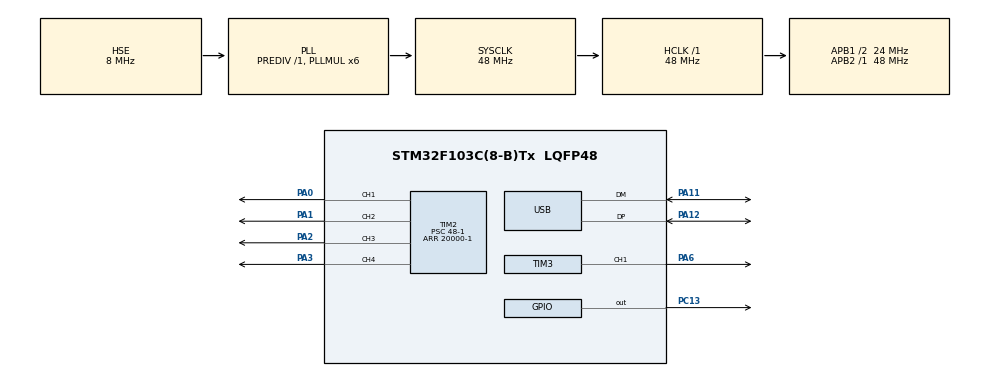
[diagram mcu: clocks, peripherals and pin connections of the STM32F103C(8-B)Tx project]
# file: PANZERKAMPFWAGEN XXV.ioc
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Mcu.Family=STM32F1
Mcu.Name=STM32F103C(8-B)Tx
Mcu.Package=LQFP48
NVIC.PriorityGroup=NVIC_PRIORITYGROUP_4
NVIC.USB_LP_CAN1_RX0_IRQn=true\:0\:0\:false\:false\:true\:false\:true
PA0-WKUP.Signal=S_TIM2_CH1_ETR
PA1.Signal=S_TIM2_CH2
PA11.Mode=Device
PA11.Signal=USB_DM
PA12.Mode=Device
PA12.Signal=USB_DP
PA13.Mode=Serial_Wire
PA13.Signal=SYS_JTMS-SWDIO
PA14.Mode=Serial_Wire
PA14.Signal=SYS_JTCK-SWCLK
PA2.Signal=S_TIM2_CH3
PA3.Signal=S_TIM2_CH4
PA6.Signal=S_TIM3_CH1
PC13-TAMPER-RTC.Signal=GPIO_Output
PC14-OSC32_IN.Mode=LSE-External-Oscillator
PC14-OSC32_IN.Signal=RCC_OSC32_IN
PC15-OSC32_OUT.Mode=LSE-External-Oscillator
PC15-OSC32_OUT.Signal=RCC_OSC32_OUT
PD0-OSC_IN.Mode=HSE-External-Oscillator
PD0-OSC_IN.Signal=RCC_OSC_IN
PD1-OSC_OUT.Mode=HSE-External-Oscillator
PD1-OSC_OUT.Signal=RCC_OSC_OUT
ProjectManager.HeapSize=0x200
ProjectManager.StackSize=0x400
ProjectManager.TargetToolchain=MDK-ARM V5.27
RCC.AHBFreq_Value=48000000
RCC.APB1CLKDivider=RCC_HCLK_DIV2
RCC.APB1Freq_Value=24000000
RCC.APB1TimFreq_Value=48000000
RCC.APB2Freq_Value=48000000
RCC.APB2TimFreq_Value=48000000
RCC.HCLKFreq_Value=48000000
RCC.PLLMUL=RCC_PLL_MUL6
RCC.SYSCLKFreq_VALUE=48000000
RCC.SYSCLKSource=RCC_SYSCLKSOURCE_PLLCLK
RCC.USBFreq_Value=48000000
SH.S_TIM2_CH1_ETR.0=TIM2_CH1,PWM Generation1 CH1
SH.S_TIM2_CH2.0=TIM2_CH2,PWM Generation2 CH2
SH.S_TIM2_CH3.0=TIM2_CH3,PWM Generation3 CH3
SH.S_TIM2_CH4.0=TIM2_CH4,PWM Generation4 CH4
SH.S_TIM3_CH1.0=TIM3_CH1,PWM Generation1 CH1
TIM2.Channel-PWM\ Generation1\ CH1=TIM_CHANNEL_1
TIM2.Channel-PWM\ Generation2\ CH2=TIM_CHANNEL_2
TIM2.Channel-PWM\ Generation3\ CH3=TIM_CHANNEL_3
TIM2.Channel-PWM\ Generation4\ CH4=TIM_CHANNEL_4
TIM2.Period=20000-1
TIM2.Prescaler=48-1
TIM3.Channel-PWM\ Generation1\ CH1=TIM_CHANNEL_1
TIM3.Period=20000-1
TIM3.Prescaler=48-1
USB_DEVICE.CLASS_NAME_FS=CDC
USB_DEVICE.PRODUCT_STRING_CDC_FS=PANZERKAMPFAGEN XXV
USB_DEVICE.VirtualMode=Cdc
USB_DEVICE.VirtualModeFS=Cdc_FS
VP_USB_DEVICE_VS_USB_DEVICE_CDC_FS.Mode=CDC_FS
board=custom

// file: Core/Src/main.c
/* USER CODE BEGIN Header */
/**
  ******************************************************************************
  * @file           : main.c
  * @brief          : Main program body
  ******************************************************************************
  * @attention
  *
  * <h2><center>&copy; Copyright (c) 2020 STMicroelectronics.
  * All rights reserved.</center></h2>
  *
  * This software component is licensed by ST under BSD 3-Clause license,
  * the "License"; You may not use this file except in compliance with the
  * License. You may obtain a copy of the License at:
  *                        opensource.org/licenses/BSD-3-Clause
  *
  ******************************************************************************
  */
/* USER CODE END Header */
#include "main.h"
#include "usb_device.h"

/* USER CODE BEGIN Includes */
#include "usbd_cdc_if.h"
/* USER CODE END Includes */

TIM_HandleTypeDef htim2;
TIM_HandleTypeDef htim3;

/* USER CODE BEGIN PV */
//int led = 0;
/* USER CODE END PV */

void SystemClock_Config(void);
static void MX_GPIO_Init(void);
static void MX_TIM2_Init(void);
static void MX_TIM3_Init(void);

int main(void)
{

  /* MCU Configuration--------------------------------------------------------*/

  /* Reset of all peripherals, Initializes the Flash interface and the Systick. */
  HAL_Init();

  /* Configure the system clock */
  SystemClock_Config();

  /* Initialize all configured peripherals */
  MX_GPIO_Init();
  MX_TIM2_Init();
  MX_TIM3_Init();
  MX_USB_DEVICE_Init();

  /* Infinite loop */
  /* USER CODE BEGIN WHILE */
	HAL_TIM_PWM_Start(&htim2,TIM_CHANNEL_1);
  HAL_TIM_PWM_Start(&htim2,TIM_CHANNEL_2);
	HAL_TIM_PWM_Start(&htim2,TIM_CHANNEL_3);
	HAL_TIM_PWM_Start(&htim2,TIM_CHANNEL_4);
	HAL_TIM_PWM_Start(&htim3,TIM_CHANNEL_1);

//	volatile uint32_t *servos[5] = {&TIM2->CCR1,&TIM2->CCR2,&TIM2->CCR3,&TIM2->CCR4,&TIM3->CCR1};
	while (1)
  {
//		HAL_GPIO_WritePin(GPIOC,GPIO_PIN_13,led);
//
//		for(uint16_t angle = 500;angle <= 1500;angle+=100){
//			*servos[0] = angle;
//			HAL_Delay(50);
//		}
////		for(uint16_t angle = 1500;angle >= 500;angle-=100){
//			TIM2->CCR1 = angle;
//			HAL_Delay(50);
//		}
    /* USER CODE END WHILE */

  }
}

void SystemClock_Config(void)
{
  RCC_OscInitTypeDef RCC_OscInitStruct = {0};
  RCC_ClkInitTypeDef RCC_ClkInitStruct = {0};
  RCC_PeriphCLKInitTypeDef PeriphClkInit = {0};

  /** Initializes the RCC Oscillators according to the specified parameters
  * in the RCC_OscInitTypeDef structure.
  */
  RCC_OscInitStruct.OscillatorType = RCC_OSCILLATORTYPE_HSE;
  RCC_OscInitStruct.HSEState = RCC_HSE_ON;
  RCC_OscInitStruct.HSEPredivValue = RCC_HSE_PREDIV_DIV1;
  RCC_OscInitStruct.HSIState = RCC_HSI_ON;
  RCC_OscInitStruct.PLL.PLLState = RCC_PLL_ON;
  RCC_OscInitStruct.PLL.PLLSource = RCC_PLLSOURCE_HSE;
  RCC_OscInitStruct.PLL.PLLMUL = RCC_PLL_MUL6;
  if (HAL_RCC_OscConfig(&RCC_OscInitStruct) != HAL_OK)
  {
    Error_Handler();
  }
  /** Initializes the CPU, AHB and APB buses clocks
  */
  RCC_ClkInitStruct.ClockType = RCC_CLOCKTYPE_HCLK|RCC_CLOCKTYPE_SYSCLK
                              |RCC_CLOCKTYPE_PCLK1|RCC_CLOCKTYPE_PCLK2;
  RCC_ClkInitStruct.SYSCLKSource = RCC_SYSCLKSOURCE_PLLCLK;
  RCC_ClkInitStruct.AHBCLKDivider = RCC_SYSCLK_DIV1;
  RCC_ClkInitStruct.APB1CLKDivider = RCC_HCLK_DIV2;
  RCC_ClkInitStruct.APB2CLKDivider = RCC_HCLK_DIV1;

  if (HAL_RCC_ClockConfig(&RCC_ClkInitStruct, FLASH_LATENCY_1) != HAL_OK)
  {
    Error_Handler();
  }
  PeriphClkInit.PeriphClockSelection = RCC_PERIPHCLK_USB;
  PeriphClkInit.UsbClockSelection = RCC_USBCLKSOURCE_PLL;
  if (HAL_RCCEx_PeriphCLKConfig(&PeriphClkInit) != HAL_OK)
  {
    Error_Handler();
  }
}

static void MX_TIM2_Init(void)
{

  TIM_MasterConfigTypeDef sMasterConfig = {0};
  TIM_OC_InitTypeDef sConfigOC = {0};

  htim2.Instance = TIM2;
  htim2.Init.Prescaler = 48-1;
  htim2.Init.CounterMode = TIM_COUNTERMODE_UP;
  htim2.Init.Period = 20000-1;
  htim2.Init.ClockDivision = TIM_CLOCKDIVISION_DIV1;
  htim2.Init.AutoReloadPreload = TIM_AUTORELOAD_PRELOAD_DISABLE;
  if (HAL_TIM_PWM_Init(&htim2) != HAL_OK)
  {
    Error_Handler();
  }
  sMasterConfig.MasterOutputTrigger = TIM_TRGO_RESET;
  sMasterConfig.MasterSlaveMode = TIM_MASTERSLAVEMODE_DISABLE;
  if (HAL_TIMEx_MasterConfigSynchronization(&htim2, &sMasterConfig) != HAL_OK)
  {
    Error_Handler();
  }
  sConfigOC.OCMode = TIM_OCMODE_PWM1;
  sConfigOC.Pulse = 0;
  sConfigOC.OCPolarity = TIM_OCPOLARITY_HIGH;
  sConfigOC.OCFastMode = TIM_OCFAST_DISABLE;
  if (HAL_TIM_PWM_ConfigChannel(&htim2, &sConfigOC, TIM_CHANNEL_1) != HAL_OK)
  {
    Error_Handler();
  }
  if (HAL_TIM_PWM_ConfigChannel(&htim2, &sConfigOC, TIM_CHANNEL_2) != HAL_OK)
  {
    Error_Handler();
  }
  if (HAL_TIM_PWM_ConfigChannel(&htim2, &sConfigOC, TIM_CHANNEL_3) != HAL_OK)
  {
    Error_Handler();
  }
  if (HAL_TIM_PWM_ConfigChannel(&htim2, &sConfigOC, TIM_CHANNEL_4) != HAL_OK)
  {
    Error_Handler();
  }
  HAL_TIM_MspPostInit(&htim2);

}

static void MX_TIM3_Init(void)
{

  TIM_MasterConfigTypeDef sMasterConfig = {0};
  TIM_OC_InitTypeDef sConfigOC = {0};

  htim3.Instance = TIM3;
  htim3.Init.Prescaler = 48-1;
  htim3.Init.CounterMode = TIM_COUNTERMODE_UP;
  htim3.Init.Period = 20000-1;
  htim3.Init.ClockDivision = TIM_CLOCKDIVISION_DIV1;
  htim3.Init.AutoReloadPreload = TIM_AUTORELOAD_PRELOAD_DISABLE;
  if (HAL_TIM_PWM_Init(&htim3) != HAL_OK)
  {
    Error_Handler();
  }
  sMasterConfig.MasterOutputTrigger = TIM_TRGO_RESET;
  sMasterConfig.MasterSlaveMode = TIM_MASTERSLAVEMODE_DISABLE;
  if (HAL_TIMEx_MasterConfigSynchronization(&htim3, &sMasterConfig) != HAL_OK)
  {
    Error_Handler();
  }
  sConfigOC.OCMode = TIM_OCMODE_PWM1;
  sConfigOC.Pulse = 0;
  sConfigOC.OCPolarity = TIM_OCPOLARITY_HIGH;
  sConfigOC.OCFastMode = TIM_OCFAST_DISABLE;
  if (HAL_TIM_PWM_ConfigChannel(&htim3, &sConfigOC, TIM_CHANNEL_1) != HAL_OK)
  {
    Error_Handler();
  }
  HAL_TIM_MspPostInit(&htim3);

}

static void MX_GPIO_Init(void)
{
  GPIO_InitTypeDef GPIO_InitStruct = {0};

  /* GPIO Ports Clock Enable */
  __HAL_RCC_GPIOC_CLK_ENABLE();
  __HAL_RCC_GPIOD_CLK_ENABLE();
  __HAL_RCC_GPIOA_CLK_ENABLE();

  /*Configure GPIO pin Output Level */
  HAL_GPIO_WritePin(GPIOC, GPIO_PIN_13, GPIO_PIN_RESET);

  /*Configure GPIO pin : PC13 */
  GPIO_InitStruct.Pin = GPIO_PIN_13;
  GPIO_InitStruct.Mode = GPIO_MODE_OUTPUT_PP;
  GPIO_InitStruct.Pull = GPIO_NOPULL;
  GPIO_InitStruct.Speed = GPIO_SPEED_FREQ_LOW;
  HAL_GPIO_Init(GPIOC, &GPIO_InitStruct);

}

void Error_Handler(void)
{
}

/************************ (C) COPYRIGHT STMicroelectronics *****END OF FILE****/
